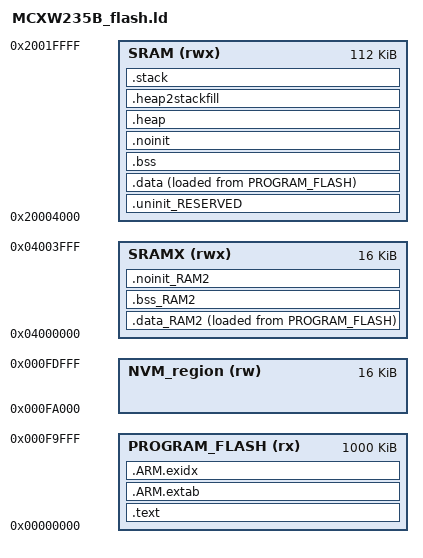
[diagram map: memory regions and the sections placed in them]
GROUP (
  "libgcc.a"
  "libc_nano.a"
  "libm.a"
  "libcr_newlib_nohost.a"
)

FLASH_START                  = 0x0;
FLASH_SIZE                   = 0xFE000;
FLASH_END                    = FLASH_START + FLASH_SIZE - 1;
FLASH_SECTOR_SIZE            = 0x2000; /* 8KB */

NV_STORAGE_END_ADDRESS       = FLASH_END;
NV_STORAGE_MAX_SECTORS       = 2;
NV_STORAGE_SECTOR_SIZE       = FLASH_SECTOR_SIZE;
NV_STORAGE_SIZE              = FLASH_SECTOR_SIZE * NV_STORAGE_MAX_SECTORS;
NV_STORAGE_START_ADDRESS     = NV_STORAGE_END_ADDRESS - NV_STORAGE_SIZE + 1;

m_text_end                   = NV_STORAGE_START_ADDRESS - 1;
m_text_start                 = 0x0;
m_text_size                  = m_text_end - m_text_start + 1;

MEMORY
{
  /* Define each memory region */
  PROGRAM_FLASH (rx) : ORIGIN = m_text_start, LENGTH = m_text_size
  NVM_region (rw) : ORIGIN = NV_STORAGE_START_ADDRESS, LENGTH = NV_STORAGE_SIZE    
  SRAM (rwx) : ORIGIN = 0x20004000, LENGTH = 0x1c000 /* 112K bytes (alias RAM) */  
  SRAMX (rwx) : ORIGIN = 0x4000000, LENGTH = 0x4000 /* 16K bytes (alias RAM2) */  
}

  /* Define a symbol for the top of each memory region */
  __base_PROGRAM_FLASH = 0x0  ; /* PROGRAM_FLASH */  
  __base_Flash = 0x0 ; /* Flash */  
  __top_PROGRAM_FLASH = 0x0 + 0xfe000 ; /* 1016K bytes */  
  __top_Flash = 0x0 + 0xfe000 ; /* 1016K bytes */  
  __base_SRAM = 0x20004000  ; /* SRAM */  
  __base_RAM = 0x20004000 ; /* RAM */  
  __top_SRAM = 0x20004000 + 0x1c000 ; /* 112K bytes */  
  __top_RAM = 0x20004000 + 0x1c000 ; /* 112K bytes */  
  __base_SRAMX = 0x4000000  ; /* SRAMX */  
  __base_RAM2 = 0x4000000 ; /* RAM2 */  
  __top_SRAMX = 0x4000000 + 0x4000 ; /* 16K bytes */  
  __top_RAM2 = 0x4000000 + 0x4000 ; /* 16K bytes */  

ENTRY(ResetISR)

SECTIONS
{
     /* MAIN TEXT SECTION */
    .text : ALIGN(4)
    {
        FILL(0xff)
        __vectors_start__ = ABSOLUTE(.) ;
        KEEP(*(.isr_vector))
        /* Global Section Table */
        . = ALIGN(4) ;
        __section_table_start = .;
        __data_section_table = .;
        LONG(LOADADDR(.data));
        LONG(    ADDR(.data));
        LONG(  SIZEOF(.data));
        LONG(LOADADDR(.data_RAM2));
        LONG(    ADDR(.data_RAM2));
        LONG(  SIZEOF(.data_RAM2));
        __data_section_table_end = .;
        __bss_section_table = .;
        LONG(    ADDR(.bss));
        LONG(  SIZEOF(.bss));
        LONG(    ADDR(.bss_RAM2));
        LONG(  SIZEOF(.bss_RAM2));
        __bss_section_table_end = .;
        __section_table_end = . ;
        /* End of Global Section Table */

        *(.after_vectors*)

       *(.text*)
       KEEP(*freertos*/tasks.o(.rodata*)) /* FreeRTOS Debug Config */
       *(.rodata .rodata.* .constdata .constdata.*)
       . = ALIGN(4);
    } > PROGRAM_FLASH
 
    _etext = .;
        
    /* DATA section for SRAMX */

    .data_RAM2 : ALIGN(4)
    {
        FILL(0xff)
        PROVIDE(__start_data_RAM2 = .) ;
        PROVIDE(__start_data_SRAMX = .) ;
        *(.ramfunc.$RAM2)
        *(.ramfunc.$SRAMX)
        *(.data.$RAM2)
        *(.data.$SRAMX)
        *(.data.$RAM2.*)
        *(.data.$SRAMX.*)
        . = ALIGN(4) ;
	    PROVIDE(__start_NVM_TABLE = .);
	    KEEP(*(.NVM_TABLE));
	    PROVIDE(__stop_NVM_TABLE = .);
	    . = ALIGN(4);
        PROVIDE(__end_data_RAM2 = .) ;
        PROVIDE(__end_data_SRAMX = .) ;
     } > SRAMX AT>PROGRAM_FLASH

    /* MAIN DATA SECTION */
    .uninit_RESERVED (NOLOAD) : ALIGN(4)
    {
        _start_uninit_RESERVED = .;
        KEEP(*(.bss.$RESERVED*))
       . = ALIGN(4) ;
        _end_uninit_RESERVED = .;
    } > SRAM AT> SRAM

    /* Main DATA section (SRAM) */
    .data : ALIGN(4)
    {
       FILL(0xff)
       _data = . ;
       PROVIDE(__start_data_RAM = .) ;
       PROVIDE(__start_data_SRAM = .) ;
       *(vtable)
       *(.ramfunc*)
       KEEP(*(CodeQuickAccess))
       KEEP(*(DataQuickAccess))
       *(RamFunction)
       *(.data*)
       . = ALIGN(4) ;
       _edata = . ;
       PROVIDE(__end_data_RAM = .) ;
       PROVIDE(__end_data_SRAM = .) ;
    } > SRAM AT>PROGRAM_FLASH

    /* BSS section for SRAMX */
    .bss_RAM2 : ALIGN(4)
    {
       PROVIDE(__start_bss_RAM2 = .) ;
       PROVIDE(__start_bss_SRAMX = .) ;
       *(.bss.$RAM2)
       *(.bss.$SRAMX)
       *(.bss.$RAM2.*)
       *(.bss.$SRAMX.*)
       . = ALIGN (. != 0 ? 4 : 1) ; /* avoid empty segment */
       PROVIDE(__end_bss_RAM2 = .) ;
       PROVIDE(__end_bss_SRAMX = .) ;
    } > SRAMX AT> SRAMX

    /* MAIN BSS SECTION */
    .bss : ALIGN(4)
    {
        _bss = .;
        PROVIDE(__start_bss_RAM = .) ;
        PROVIDE(__start_bss_SRAM = .) ;
        *(.bss*)
        *(COMMON)
        . = ALIGN(4) ;
        _ebss = .;
        PROVIDE(__end_bss_RAM = .) ;
        PROVIDE(__end_bss_SRAM = .) ;
        PROVIDE(end = .);
    } > SRAM AT> SRAM

    /* NOINIT section for SRAMX */
    .noinit_RAM2 (NOLOAD) : ALIGN(4)
    {
       PROVIDE(__start_noinit_RAM2 = .) ;
       PROVIDE(__start_noinit_SRAMX = .) ;
       *(.noinit.$RAM2)
       *(.noinit.$SRAMX)
       *(.noinit.$RAM2.*)
       *(.noinit.$SRAMX.*)
       . = ALIGN(4) ;
       PROVIDE(__end_noinit_RAM2 = .) ;
       PROVIDE(__end_noinit_SRAMX = .) ;
    } > SRAMX AT> SRAMX

    /* DEFAULT NOINIT SECTION */
    .noinit (NOLOAD): ALIGN(4)
    {
        _noinit = .;
        PROVIDE(__start_noinit_RAM = .) ;
        PROVIDE(__start_noinit_SRAM = .) ;
        *(.noinit*)
         . = ALIGN(4) ;
        _end_noinit = .;
       PROVIDE(__end_noinit_RAM = .) ;
       PROVIDE(__end_noinit_SRAM = .) ;        
    } > SRAM AT> SRAM

    /*
     * for exception handling/unwind - some Newlib functions (in common
     * with C++ and STDC++) use this.
     */
    .ARM.extab : ALIGN(4)
    {
        *(.ARM.extab* .gnu.linkonce.armextab.*)
    } > PROGRAM_FLASH

    .ARM.exidx : ALIGN(4)
    {
        __exidx_start = .;
        *(.ARM.exidx* .gnu.linkonce.armexidx.*)
        __exidx_end = .;
    } > PROGRAM_FLASH

    /* Reserve and place Heap within memory map */
    _HeapSize = 0x0;
    .heap :  ALIGN(4)
    {
        _pvHeapStart = .;
        . += _HeapSize;
        . = ALIGN(4);
        _pvHeapLimit = .;
    } > SRAM

     _StackSize = 0x400;
     /* Reserve space in memory for Stack */
    .heap2stackfill  :
    {
        . += _StackSize;
    } > SRAM
    /* Locate actual Stack in memory map */
    .stack ORIGIN(SRAM) + LENGTH(SRAM) - _StackSize - 0:  ALIGN(4)
    {
        _vStackBase = .;
        . = ALIGN(4);
        _vStackTop = . + _StackSize;
    } > SRAM

    /* Provide basic symbols giving location and size of main text
     * block, including initial values of RW data sections. Note that
     * these will need extending to give a complete picture with
     * complex images (e.g multiple Flash banks).
     */
    _image_start = LOADADDR(.text);
    _image_end = LOADADDR(.data) + SIZEOF(.data);
    _image_size = _image_end - _image_start;
}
